# ATSAMV70Q19B register map
Vendor: Microchip Technology; Series: SAMV70; File version: 0
CPU: CM7 r1p1, little endian, MPU, FPU, 3 interrupt priority bits
Registers are 32-bit, read-write, reset 0x0 unless marked. A register's access mark holds for its fields unless they carry their own. Offsets are from the block's base; [hi:lo] are bit positions; lines under a group give offsets from that group; {n}, {i} and the like mark numbered series.

## MATRIX — AHB Bus Matrix
Base 0x40088000; register names take the prefix MATRIX_
{0x0+4i} MATRIX_MCFG[{i}] (i=0..12) — Master Configuration Register 0
  [2:0] ULBT — Undefined Length Burst Type
    0=UNLTD_LENGTH (Unlimited Length Burst-No predicted end of burst is generated, therefore INCR bursts coming from this master can only be broken if the Slave Slot Cycle Limit is reached. If the Slot Cycle Limit is not reached, the burst is normally completed by the master, at the latest, on the next AHB 1-Kbyte address boundary, allowing up to 256-beat word bursts or 128-beat double-word bursts.This value should not be used in the very particular case of a master capable of performing back-to-back undefined length bursts on a single slave, since this could indefinitely freeze the slave arbitration and thus prevent another master from accessing this slave.); 1=SINGLE_ACCESS (Single Access-The undefined length burst is treated as a succession of single accesses, allowing re-arbitration at each beat of the INCR burst or bursts sequence.); 2=_4BEAT_BURST (4-beat Burst-The undefined length burst or bursts sequence is split into 4-beat bursts or less, allowing re-arbitration every 4 beats.); 3=_8BEAT_BURST (8-beat Burst-The undefined length burst or bursts sequence is split into 8-beat bursts or less, allowing re-arbitration every 8 beats.); 4=_16BEAT_BURST (16-beat Burst-The undefined length burst or bursts sequence is split into 16-beat bursts or less, allowing re-arbitration every 16 beats.); 5=_32BEAT_BURST (32-beat Burst -The undefined length burst or bursts sequence is split into 32-beat bursts or less, allowing re-arbitration every 32 beats.); 6=_64BEAT_BURST (64-beat Burst-The undefined length burst or bursts sequence is split into 64-beat bursts or less, allowing re-arbitration every 64 beats.); 7=_128BEAT_BURST (128-beat Burst-The undefined length burst or bursts sequence is split into 128-beat bursts or less, allowing re-arbitration every 128 beats.)
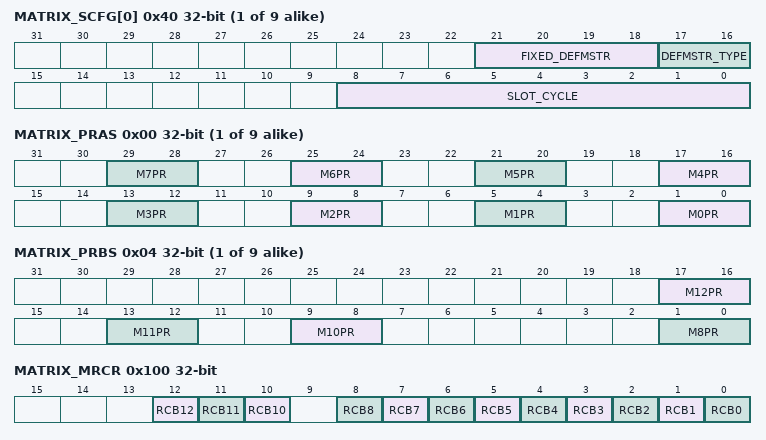
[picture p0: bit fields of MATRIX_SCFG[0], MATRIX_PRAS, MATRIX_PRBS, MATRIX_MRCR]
{0x40+4i} MATRIX_SCFG[{i}] (i=0..8) — Slave Configuration Register 0
  [21:18] FIXED_DEFMSTR — Fixed Default Master
  [17:16] DEFMSTR_TYPE — Default Master Type
    0=NONE (No Default Master-At the end of the current slave access, if no other master request is pending, the slave is disconnected from all masters.This results in a one clock cycle latency for the first access of a burst transfer or for a single access.); 1=LAST (Last Default Master-At the end of the current slave access, if no other master request is pending, the slave stays connected to the last master having accessed it.This results in not having one clock cycle latency when the last master tries to access the slave again.); 2=FIXED (Fixed Default Master-At the end of the current slave access, if no other master request is pending, the slave connects to the fixed master the number that has been written in the FIXED_DEFMSTR field.This results in not having one clock cycle latency when the fixed master tries to access the slave again.)
  [8:0] SLOT_CYCLE — Maximum Bus Grant Duration for Masters
{0x80+8i} MATRIX_PR[{i}] (i=0..8) group — Priority Register A for Slave 0
  0x00 MATRIX_PRAS — Priority Register A for Slave 0
    [4n+1:4n] M{n}PR (n=0..7) — Master {n} Priority
  0x04 MATRIX_PRBS — Priority Register B for Slave 0
    [17:16] M12PR — Master 12 Priority
    [13:12] M11PR — Master 11 Priority
    [9:8] M10PR — Master 10 Priority
    [1:0] M8PR — Master 8 Priority
0x100 MATRIX_MRCR — Master Remap Control Register
  [12] RCB12 — Remap Command Bit for Master 12
  [11] RCB11 — Remap Command Bit for Master 11
  [10] RCB10 — Remap Command Bit for Master 10
  [n] RCB{n} (n=0..8) — Remap Command Bit for Master {n}
0x110 CCFG_CAN0 — CAN0 Configuration Register
  [31:16] CAN0DMABA — CAN0 DMA Base Address
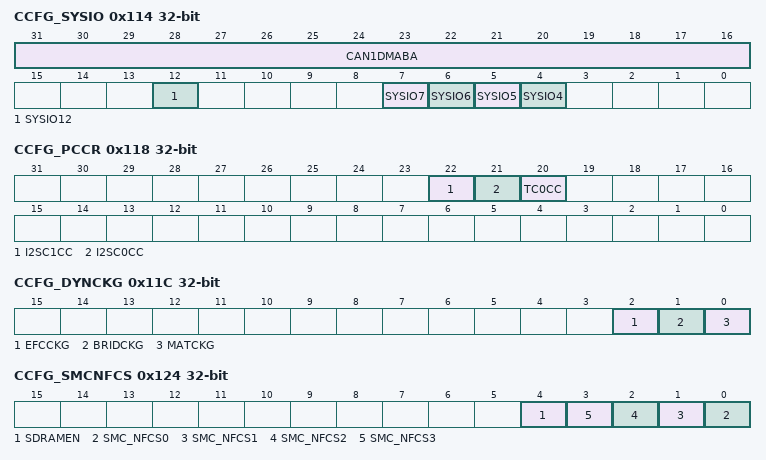
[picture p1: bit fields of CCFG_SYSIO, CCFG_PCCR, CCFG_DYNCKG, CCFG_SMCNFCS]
0x114 CCFG_SYSIO — System I/O and CAN1 Configuration Register
  [31:16] CAN1DMABA — CAN1 DMA Base Address
  [12] SYSIO12 — PB12 or ERASE Assignment
  [7] SYSIO7 — PB7 or TCK/SWCLK Assignment
  [6] SYSIO6 — PB6 or TMS/SWDIO Assignment
  [5] SYSIO5 — PB5 or TDO/TRACESWO Assignment
  [4] SYSIO4 — PB4 or TDI Assignment
0x118 CCFG_PCCR — Peripheral Clock Configuration Register
  [22] I2SC1CC — I2SC1 Clock Configuration
  [21] I2SC0CC — I2SC0 Clock Configuration
  [20] TC0CC — TC0 Clock Configuration
0x11C CCFG_DYNCKG — Dynamic Clock Gating Register
  [2] EFCCKG — EFC Dynamic Clock Gating Enable
  [1] BRIDCKG — Bridge Dynamic Clock Gating Enable
  [0] MATCKG — MATRIX Dynamic Clock Gating
0x124 CCFG_SMCNFCS — SMC NAND Flash Chip Select Configuration Register
  [4] SDRAMEN — SDRAM Enable
  [n] SMC_NFCS{n} (n=0..3) — SMC NAND Flash Chip Select {n} Assignment
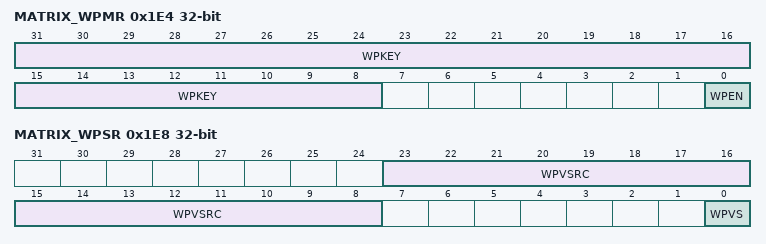
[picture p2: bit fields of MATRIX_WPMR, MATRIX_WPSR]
0x1E4 MATRIX_WPMR — Write Protection Mode Register
  [31:8] WPKEY — Write Protection Key
    0x4D4154=PASSWD (Writing any other value in this field aborts the write operation of the WPEN bit.Always reads as 0.)
  [0] WPEN — Write Protection Enable
0x1E8 MATRIX_WPSR ro — Write Protection Status Register
  [23:8] WPVSRC — Write Protection Violation Source
  [0] WPVS — Write Protection Violation Status

## Notices in the file
Copyright (c) 2017 Microchip Technology Inc.
SPDX-License-Identifier: Apache-2.0
Licensed under the Apache License, Version 2.0 (the "License");
you may not use this file except in compliance with the License.
You may obtain a copy of the License at
http://www.apache.org/licenses/LICENSE-2.0
Unless required by applicable law or agreed to in writing, software
distributed under the License is distributed on an "AS IS" BASIS,
WITHOUT WARRANTIES OR CONDITIONS OF ANY KIND, either express or implied.
See the License for the specific language governing permissions and
limitations under the License.
